# SKEAZN642 register map
Vendor: Freescale Semiconductor, Inc.; Series: Kinetis_EA; File version: 1.6
CPU: CM0PLUS r0p0, little endian, no MPU, no FPU, VTOR, 2 interrupt priority bits
Registers are 32-bit, read-write, reset 0x0 unless marked. A register's access mark holds for its fields unless they carry their own. Offsets are from the block's base; [hi:lo] are bit positions.

## GPIOA — General Purpose Input/Output
Base 0x400FF000; register names take the prefix GPIOA_
0x00 PDOR — Port Data Output Register
  [31:0] PDO — Port Data Output
    0=Logic level 0 is driven on pin, provided pin is configured for general-purpose output; 1=Logic level 1 is driven on pin, provided pin is configured for general-purpose output
0x04 PSOR wo — Port Set Output Register
  [31:0] PTSO — Port Set Output
    0=Corresponding bit in PDORn does not change; 1=Corresponding bit in PDORn is set to logic 1
0x08 PCOR wo — Port Clear Output Register
  [31:0] PTCO — Port Clear Output
    0=Corresponding bit in PDORn does not change; 1=Corresponding bit in PDORn is cleared to logic 0
0x0C PTOR wo — Port Toggle Output Register
  [31:0] PTTO — Port Toggle Output
    0=Corresponding bit in PDORn does not change; 1=Corresponding bit in PDORn is set to the inverse of its existing logic state
0x10 PDIR ro — Port Data Input Register
  [31:0] PDI — Port Data Input
    0=Pin logic level is logic 0, or is not configured for use by digital function; 1=Pin logic level is logic 1
0x14 PDDR — Port Data Direction Register
  [31:0] PDD — Port Data Direction
    0=Pin is configured as general-purpose input, for the GPIO function. The pin will be high-Z if the port input is disabled in GPIOx_PIDR register.; 1=Pin is configured as general-purpose output, for the GPIO function
0x18 PIDR reset 0xFFFFFFFF — Port Input Disable Register
  [31:0] PID — Port Input Disable
    0=Pin is configured for General Purpose Input, provided the pin is configured for any digital function; 1=Pin is not configured as General Purpose Input.Corresponding Pin Data Input Register bit will read zero

## GPIOB — General Purpose Input/Output
Base 0x400FF040; register names take the prefix GPIOB_
Registers as GPIOA.

## FGPIOA — General Purpose Input/Output
Base 0xF8000000; register names take the prefix FGPIOA_
Registers as GPIOA; these are added or differ:
0x14 PDDR — Port Data Direction Register
  [31:0] PDD — Port Data Direction
    0=Pin is configured as general-purpose input, for the GPIO function. The pin will be high-Z if the port input is disabled in FPIOx_PIDR register.; 1=Pin is configured as general-purpose output, for the GPIO function

## FGPIOB — General Purpose Input/Output
Base 0xF8000040; register names take the prefix FGPIOB_
Registers as FGPIOA.

## SystemControl — System Control Registers
Base 0xE000E000; register names take the prefix SCB_
0x08 ACTLR ro — Auxiliary Control Register,
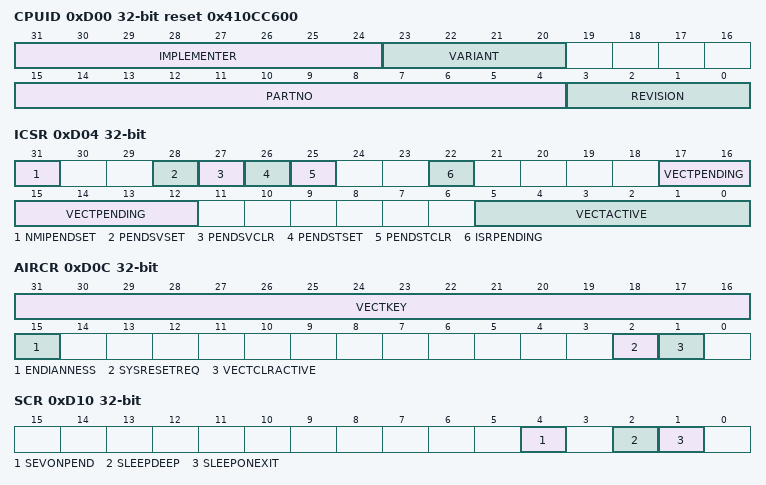
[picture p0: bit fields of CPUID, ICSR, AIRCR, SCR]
0xD00 CPUID ro reset 0x410CC600 — CPUID Base Register
  [31:24] IMPLEMENTER — Implementer code
  [23:20] VARIANT — Indicates processor revision: 0x2 = Revision 2
  [15:4] PARTNO — Indicates part number
  [3:0] REVISION — Indicates patch release: 0x0 = Patch 0
0xD04 ICSR — Interrupt Control and State Register
  [31] NMIPENDSET
    0=write: no effect; read: NMI exception is not pending; 1=write: changes NMI exception state to pending; read: NMI exception is pending
  [28] PENDSVSET
    0=write: no effect; read: PendSV exception is not pending; 1=write: changes PendSV exception state to pending; read: PendSV exception is pending
  [27] PENDSVCLR wo
    0=no effect; 1=removes the pending state from the PendSV exception
  [26] PENDSTSET
    0=write: no effect; read: SysTick exception is not pending; 1=write: changes SysTick exception state to pending; read: SysTick exception is pending
  [25] PENDSTCLR wo
    0=no effect; 1=removes the pending state from the SysTick exception
  [22] ISRPENDING ro
  [17:12] VECTPENDING ro — Exception number of the highest priority pending enabled exception
  [5:0] VECTACTIVE ro — Active exception number
0xD08 VTOR — Vector Table Offset Register
  [31:7] TBLOFF — Vector table base offset
0xD0C AIRCR — Application Interrupt and Reset Control Register
  [31:16] VECTKEY — Register key
  [15] ENDIANNESS ro
    0=Little-endian; 1=Big-endian
  [2] SYSRESETREQ wo
    0=no system reset request; 1=asserts a signal to the outer system that requests a reset
  [1] VECTCLRACTIVE wo
0xD10 SCR — System Control Register
  [4] SEVONPEND
    0=only enabled interrupts or events can wakeup the processor, disabled interrupts are excluded; 1=enabled events and all interrupts, including disabled interrupts, can wakeup the processor
  [2] SLEEPDEEP
    0=sleep; 1=deep sleep
  [1] SLEEPONEXIT
    0=o not sleep when returning to Thread mode; 1=enter sleep, or deep sleep, on return from an ISR
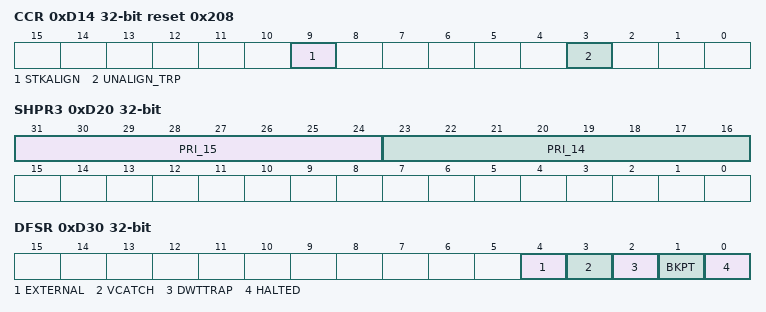
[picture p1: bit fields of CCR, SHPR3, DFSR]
0xD14 CCR ro reset 0x208 — Configuration and Control Register
  [9] STKALIGN — Indicates stack alignment on exception entry
  [3] UNALIGN_TRP — Always reads as one, indicates that all unaligned accesses generate a HardFault
0xD1C SHPR2 — System Handler Priority Register 2
  [31:24] PRI_11 — Priority of system handler 11, SVCall
0xD20 SHPR3 — System Handler Priority Register 3
  [31:24] PRI_15 — Priority of system handler 15, SysTick exception
  [23:16] PRI_14 — Priority of system handler 14, PendSV
0xD24 SHCSR — System Handler Control and State Register
  [15] SVCALLPENDED
    0=exception is not pending; 1=exception is pending
0xD30 DFSR — Debug Fault Status Register
  [4] EXTERNAL
    0=No EDBGRQ debug event; 1=EDBGRQ debug event
  [3] VCATCH
    0=No Vector catch triggered; 1=Vector catch triggered
  [2] DWTTRAP
    0=No current debug events generated by the DWT; 1=At least one current debug event generated by the DWT
  [1] BKPT
    0=No current breakpoint debug event; 1=At least one current breakpoint debug event
  [0] HALTED
    0=No active halt request debug event; 1=Halt request debug event active
